# tmpm373 register map
File version: 0.1
CPU: CM3 r2p0, little endian, no MPU, no FPU, 4 interrupt priority bits
Registers are 32-bit, read-write, reset 0x0 unless marked. A register's access mark holds for its fields unless they carry their own. Offsets are from the block's base; [hi:lo] are bit positions; {n}, {i} and the like mark numbered series.

## PF — General Purpose Input_Output Port (PF)
Base 0x40000140
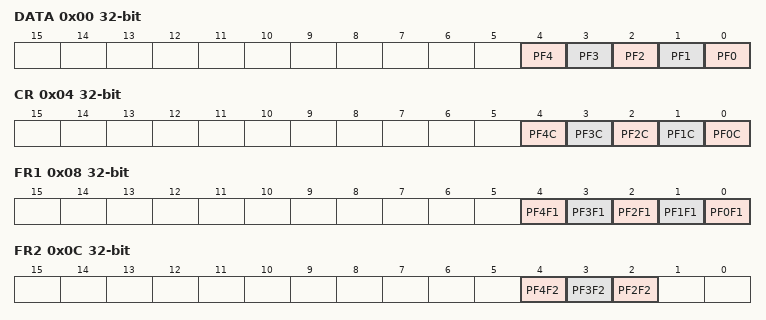
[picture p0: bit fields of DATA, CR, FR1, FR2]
0x00 DATA — PF Register
  [n] PF{n} (n=0..4)
0x04 CR — PF Control Register
  [n] PF{n}C (n=0..4)
0x08 FR1 — PF Function Register 1
  [n] PF{n}F1 (n=0..4)
0x0C FR2 — PF Function Register 2
  [4] PF4F2, [3] PF3F2, [2] PF2F2
0x10 FR3 — PF Function Register 3
  [2] PF2F3
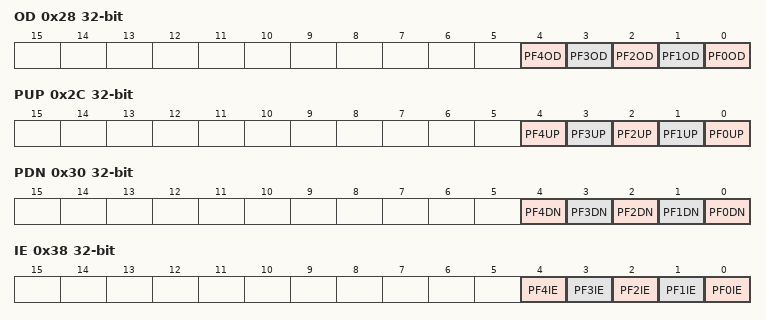
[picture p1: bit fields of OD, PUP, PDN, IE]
0x28 OD — PF Open Drain Control Register
  [n] PF{n}OD (n=0..4)
0x2C PUP — PF Pull-Up Control Register
  [n] PF{n}UP (n=0..4)
0x30 PDN — PF Pull-Down Control Register
  [n] PF{n}DN (n=0..4)
0x38 IE — PF Input Enable Control Register
  [n] PF{n}IE (n=0..4)

## PG — General Purpose Input_Output Port (PG)
Base 0x40000180
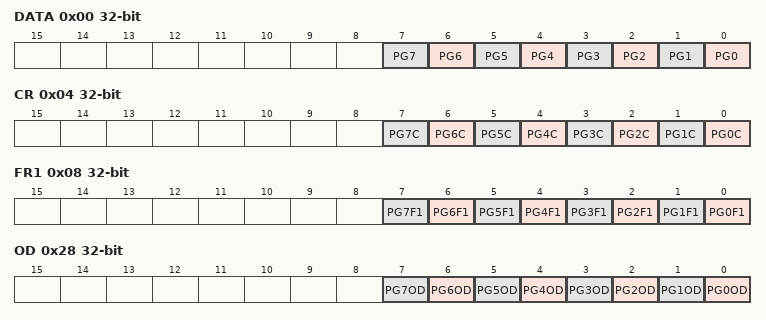
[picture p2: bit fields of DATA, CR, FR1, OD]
0x00 DATA — PG Register
  [n] PG{n} (n=0..7)
0x04 CR — PG Control Register
  [n] PG{n}C (n=0..7)
0x08 FR1 — PG Function Register 1
  [n] PG{n}F1 (n=0..7)
0x28 OD — PG Open Drain Control Register
  [n] PG{n}OD (n=0..7)
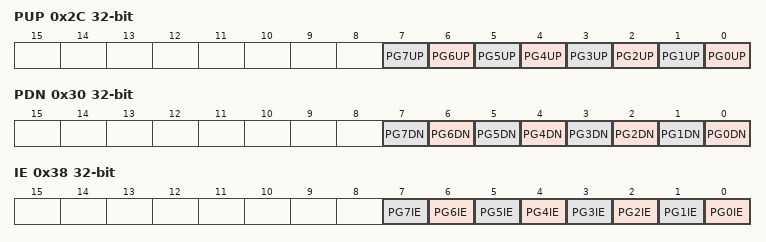
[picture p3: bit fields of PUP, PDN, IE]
0x2C PUP — PG Pull-Up Control Register
  [n] PG{n}UP (n=0..7)
0x30 PDN — PG Pull-Down Control Register
  [n] PG{n}DN (n=0..7)
0x38 IE — PG Input Enable Control Register
  [n] PG{n}IE (n=0..7)

## PI — General Purpose Input_Output Port (PI)
Base 0x40000200
0x00 DATA — PI Register
  [3] PI3
0x04 CR — PI Control Register
  [3] PI3C
0x28 OD — PI Open Drain Control Register
  [3] PI3OD
0x2C PUP — PI Pull-Up Control Register
  [3] PI3UP
0x30 PDN — PI Pull-Down Control Register
  [3] PI3DN
0x38 IE — PI Input Enable Control Register
  [3] PI3IE

## PJ — General Purpose Input_Output Port (PJ)
Base 0x40000240
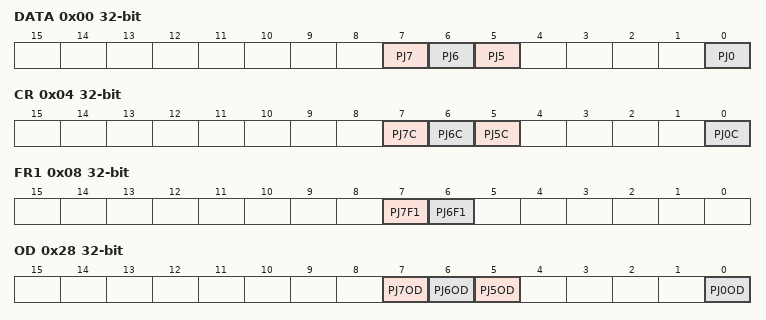
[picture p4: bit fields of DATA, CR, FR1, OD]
0x00 DATA — PJ Register
  [7] PJ7, [6] PJ6, [5] PJ5, [0] PJ0
0x04 CR — PJ Control Register
  [7] PJ7C, [6] PJ6C, [5] PJ5C, [0] PJ0C
0x08 FR1 — PJ Function Register 1
  [7] PJ7F1, [6] PJ6F1
0x28 OD — PJ Open Drain Control Register
  [7] PJ7OD, [6] PJ6OD, [5] PJ5OD, [0] PJ0OD
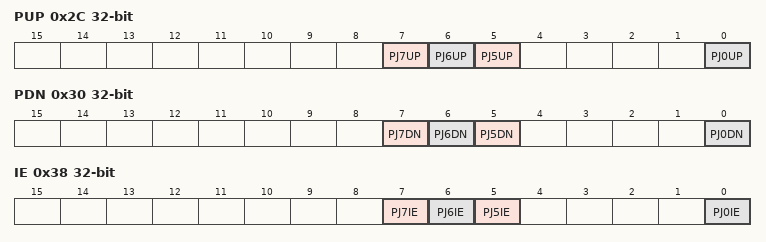
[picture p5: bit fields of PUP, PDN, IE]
0x2C PUP — PJ Pull-Up Control Register
  [7] PJ7UP, [6] PJ6UP, [5] PJ5UP, [0] PJ0UP
0x30 PDN — PJ Pull-Down Control Register
  [7] PJ7DN, [6] PJ6DN, [5] PJ5DN, [0] PJ0DN
0x38 IE — PJ Input Enable Control Register
  [7] PJ7IE, [6] PJ6IE, [5] PJ5IE, [0] PJ0IE

## PK — General Purpose Input_Output Port (PK)
Base 0x40000280
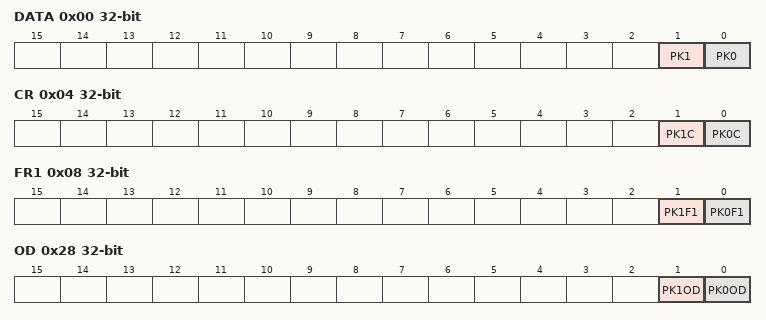
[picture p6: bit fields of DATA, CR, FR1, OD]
0x00 DATA — PK Register
  [1] PK1, [0] PK0
0x04 CR — PK Control Register
  [1] PK1C, [0] PK0C
0x08 FR1 — PK Function Register 1
  [1] PK1F1, [0] PK0F1
0x28 OD — PK Open Drain Control Register
  [1] PK1OD, [0] PK0OD
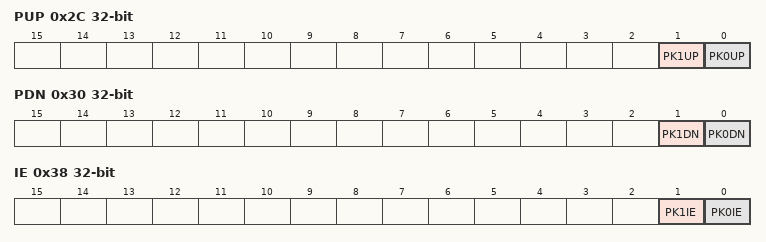
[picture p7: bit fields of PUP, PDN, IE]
0x2C PUP — PK Pull-Up Control Register
  [1] PK1UP, [0] PK0UP
0x30 PDN — PK Pull-Down Control Register
  [1] PK1DN, [0] PK0DN
0x38 IE — PK Input Enable Control Register
  [1] PK1IE, [0] PK0IE

## PM — General Purpose Input_Output Port (PM)
Base 0x40000300
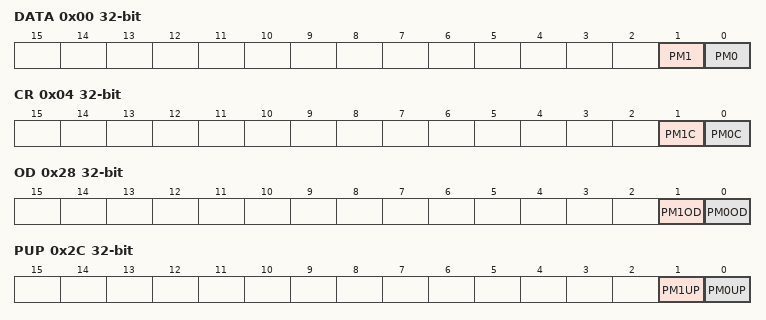
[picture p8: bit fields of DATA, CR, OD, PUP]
0x00 DATA — PM Register
  [1] PM1, [0] PM0
0x04 CR — PM Control Register
  [1] PM1C, [0] PM0C
0x28 OD — PM Open Drain Control Register
  [1] PM1OD, [0] PM0OD
0x2C PUP — PM Pull-Up Control Register
  [1] PM1UP, [0] PM0UP
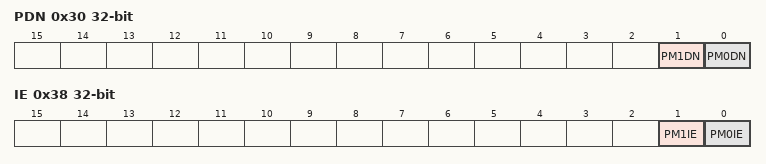
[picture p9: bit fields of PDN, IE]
0x30 PDN — PM Pull-Down Control Register
  [1] PM1DN, [0] PM0DN
0x38 IE — PM Input Enable Control Register
  [1] PM1IE, [0] PM0IE

## TB0 — 16-bit Timer_Event Counter (TB)
Base 0x40010000
Same registers: TB1 0x40010040, TB2 0x40010080, TB3 0x400100C0, TB4 0x40010100, TB5 0x40010140, TB6 0x40010180, TB7 0x400101C0
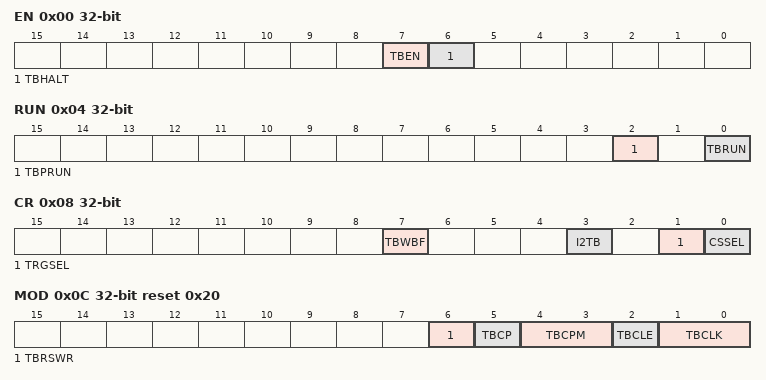
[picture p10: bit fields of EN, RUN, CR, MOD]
0x00 EN — TB Enable Register
  [7] TBEN, [6] TBHALT
0x04 RUN — TB RUN Register
  [2] TBPRUN, [0] TBRUN
0x08 CR — TB Control Register
  [7] TBWBF, [3] I2TB, [1] TRGSEL, [0] CSSEL
0x0C MOD reset 0x20 — TB Mode Register
  [6] TBRSWR, [5] TBCP wo, [4:3] TBCPM, [2] TBCLE, [1:0] TBCLK
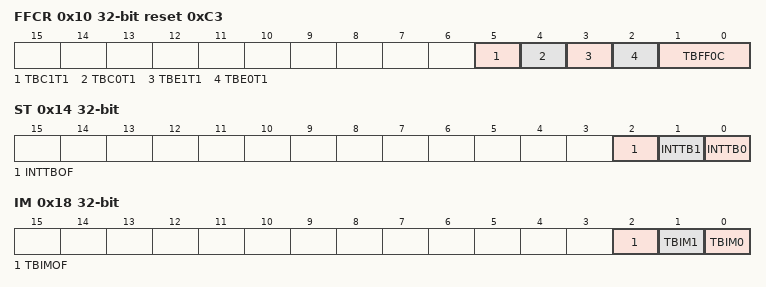
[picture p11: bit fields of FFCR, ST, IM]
0x10 FFCR reset 0xC3 — TB Flip-Flop Control Register
  [5] TBC1T1, [4] TBC0T1, [3] TBE1T1, [2] TBE0T1, [1:0] TBFF0C
0x14 ST ro — TB Status Register
  [2] INTTBOF, [1] INTTB1, [0] INTTB0
0x18 IM — TB Interrupt Mask Register
  [2] TBIMOF, [1] TBIM1, [0] TBIM0
0x1C UC ro — TB Read Capture Register
  [15:0] UC
0x20 RG0 — TB RG0 Timer Register
  [15:0] TBRG0
0x24 RG1 — TB RG1 Timer Register
  [15:0] TBRG1
0x28 CP0 ro — TB CP0 Capture Register
  [15:0] TBCP0
0x2C CP1 ro — TB CP1 Capture Register
  [15:0] TBCP1
